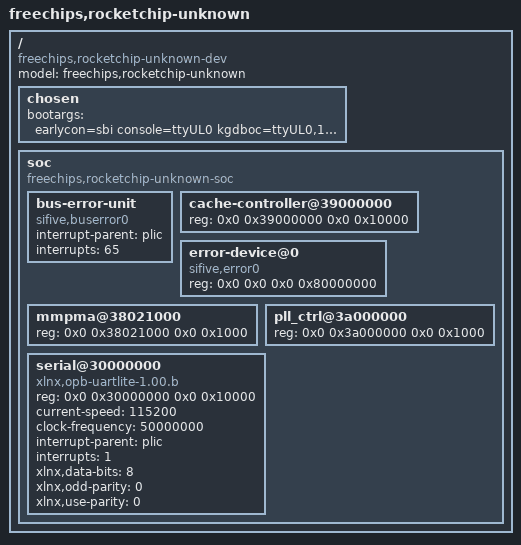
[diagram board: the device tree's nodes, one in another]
/dts-v1/;

#include NUM_CORES_H

#include "memory.dtsi"

#include "pcie.dtsi"

/ {
	#address-cells = <2>;
	#size-cells = <2>;
	compatible = "freechips,rocketchip-unknown-dev";
	model = "freechips,rocketchip-unknown";
	
	chosen {
		bootargs = "earlycon=sbi console=ttyUL0 kgdboc=ttyUL0,115200";
	};
	
	soc {
		#address-cells = <2>;
		#size-cells = <2>;
		compatible = "freechips,rocketchip-unknown-soc", "simple-bus";
		ranges;
		bus-error-unit {
			compatible = "sifive,buserror0";
			interrupt-parent = <&plic>;
			interrupts = <65>;
		};
		cache-controller@39000000 {
			reg = <0x0 0x39000000 0x0 0x10000>;
			reg-names = "control";
		};
		error-device@0 {
			compatible = "sifive,error0";
			reg = <0x0 0x0 0x0 0x80000000>;
		};
		mmpma@38021000 {
			reg = <0x0 0x38021000 0x0 0x1000>;
			reg-names = "control";
		};
		pll_ctrl@3a000000 {
			reg = <0x0 0x3a000000 0x0 0x1000>;
			reg-names = "control";
		};
		serial@30000000 {
			device_type = "serial";
			compatible = "xlnx,opb-uartlite-1.00.b";
			reg = <0x0 0x30000000 0x0 0x10000>;
			current-speed = <115200>;
			clock-frequency = <50000000>;
			interrupt-parent = <&plic>;
			interrupts = <1>;
			xlnx,data-bits = <8>;
			xlnx,odd-parity = <0>;
			xlnx,use-parity = <0>;
		};
	};
};
